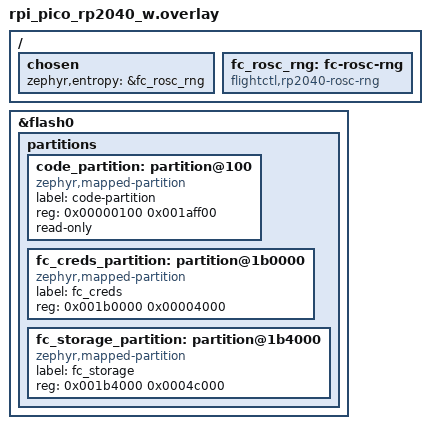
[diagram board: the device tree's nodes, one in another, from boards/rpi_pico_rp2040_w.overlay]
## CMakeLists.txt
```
# flightctl-mcu on Zephyr: the agent core, the Zephyr port and a small
# application. Built with port/zephyr/build.sh.
cmake_minimum_required(VERSION 3.20)
find_package(Zephyr REQUIRED HINTS $ENV{ZEPHYR_BASE})
project(flightctl_mcu)
# For mbedTLS too: it includes fc-mbedtls-user.h (prj.conf).
zephyr_include_directories(include)

set(ROOT ${CMAKE_CURRENT_LIST_DIR}/../..)

# WAMR (third_party/fetch-wamr.sh): fast interpreter only, as in the other
# builds.
enable_language(ASM)
set(WAMR_BUILD_PLATFORM "zephyr")
if(CONFIG_ARCH_POSIX)
    if(CMAKE_HOST_SYSTEM_PROCESSOR MATCHES "^(arm64|aarch64)")
        set(WAMR_BUILD_TARGET "AARCH64")
    else()
        set(WAMR_BUILD_TARGET "X86_64")
    endif()
elseif(CONFIG_CPU_CORTEX_M0PLUS OR CONFIG_CPU_CORTEX_M0)
    set(WAMR_BUILD_TARGET "THUMBV6M")
elseif(CONFIG_CPU_CORTEX_M)
    set(WAMR_BUILD_TARGET "THUMBV7EM")
elseif(CONFIG_XTENSA)
    set(WAMR_BUILD_TARGET "XTENSA")
else()
    message(FATAL_ERROR "flightctl-mcu: no WAMR target for this board yet")
endif()
set(WAMR_BUILD_INTERP 1)
set(WAMR_BUILD_FAST_INTERP 1)
set(WAMR_BUILD_AOT 0)
set(WAMR_BUILD_JIT 0)
set(WAMR_BUILD_LIBC_BUILTIN 0)
set(WAMR_BUILD_LIBC_WASI 0)
set(WAMR_BUILD_SIMD 0)
set(WAMR_BUILD_REF_TYPES 0)
# Instruction metering: an app call that runs past its budget traps, so an
# app in an endless loop can always be stopped (core/src/fc_apps.c).
set(WAMR_BUILD_INSTRUCTION_METERING 1)
set(WAMR_ROOT_DIR ${ROOT}/third_party/wamr)
include(${WAMR_ROOT_DIR}/build-scripts/runtime_lib.cmake)

# detools (third_party/fetch-detools.sh): firmware deltas, as in the other
# builds (CMakeLists.txt at the root).
set(DETOOLS ${ROOT}/third_party/detools/c)
set(DETOOLS_SRCS ${DETOOLS}/detools.c ${DETOOLS}/heatshrink/heatshrink_decoder.c)

target_sources(app PRIVATE
    src/main.c
    ${ROOT}/port/zephyr/fc_port_zephyr.c
    ${ROOT}/port/zephyr/fc_net_zephyr.c
    ${ROOT}/core/src/fc_agent.c
    ${ROOT}/core/src/fc_http.c
    ${ROOT}/core/src/fc_identity.c
    ${ROOT}/core/src/fc_oci.c
    ${ROOT}/core/src/fc_apps.c
    ${ROOT}/core/src/fc_appapi.c
    ${ROOT}/core/src/fc_board.c
    ${ROOT}/core/src/fc_resources.c
    ${ROOT}/core/src/fc_delta.c
    ${ROOT}/third_party/cjson/cJSON.c
    ${DETOOLS_SRCS}
    ${WAMR_RUNTIME_LIB_SOURCE})
# Boards with WiFi: the network, given at the factory, or in the field where
# the board can open an access point (with a DHCP server for installers).
if(CONFIG_WIFI)
    target_sources(app PRIVATE src/wifi.c)
endif()
if(CONFIG_WIFI AND CONFIG_NET_DHCPV4_SERVER)
    target_sources(app PRIVATE ${ROOT}/core/src/fc_prov.c)
endif()
if(CONFIG_FC_ENTROPY_RP2_ROSC)
    target_sources(app PRIVATE ${ROOT}/port/zephyr/fc_entropy_rp2.c)
endif()
# Infineon's WiFi driver (the Pico W's) keeps 20 packet buffers. Zephyr 4.5
# made them 2400 bytes each, 16 KB more than a board with 264 KB of RAM can
# give: 1600, what they were up to Zephyr 4.3 and what the board ran with, is
# an Ethernet frame and the chip's header.
if(CONFIG_WIFI_AIROC)
    zephyr_compile_definitions(AIROC_WIFI_PACKET_POOL_SIZE=1600)
endif()
# Raspberry Pi Pico boards: the USB console's conveniences.
if(CONFIG_SOC_FAMILY_RPI_PICO)
    target_sources(app PRIVATE src/board_rp2.c)
endif()
# The C heap is the port's unless the build keeps Zephyr's.
if(NOT CONFIG_COMMON_LIBC_MALLOC)
    target_sources(app PRIVATE ${ROOT}/port/zephyr/fc_heap_zephyr.c)
endif()
target_include_directories(app PRIVATE
    ${ROOT}/core/include ${ROOT}/core/src ${ROOT}/third_party/cjson ${ROOT}/port/zephyr
    ${DETOOLS} ${DETOOLS}/heatshrink)
# WAMR 2.4.5's Zephyr port includes <autoconf.h> and <version.h>, which Zephyr
# generates under zephyr/ and no longer puts on the include path as they are.
target_include_directories(app PRIVATE ${ZEPHYR_BINARY_DIR}/include/generated/zephyr)
target_compile_definitions(app PRIVATE
    CJSON_NESTING_LIMIT=32
    DETOOLS_CONFIG_FILE_IO=0 DETOOLS_CONFIG_COMPRESSION_NONE=0 DETOOLS_CONFIG_COMPRESSION_LZMA=0
    DETOOLS_CONFIG_COMPRESSION_CRLE=0 HEATSHRINK_DYNAMIC_ALLOC=1)
if(CONFIG_FC_AGENT_STACK_SIZE)
    target_compile_definitions(app PRIVATE FC_AGENT_STACK_SIZE=${CONFIG_FC_AGENT_STACK_SIZE})
endif()
set_source_files_properties(${DETOOLS_SRCS} PROPERTIES
    COMPILE_DEFINITIONS "malloc=fc_delta_alloc;free=fc_delta_free"
    COMPILE_OPTIONS "-w;-fwrapv")
```

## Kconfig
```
# flightctl-mcu application options.

config FC_SNTP_SERVER
	string "SNTP server the device takes the time from"
	default "pool.ntp.org"

config FC_HEAP_SIZE
	int "Size of the C heap (malloc), in bytes"
	default 163840
	help
	  Everything the agent allocates: TLS sessions, JSON documents, WASM
	  modules and their memory. The device reports how much of it is free.

config FC_AGENT_STACK_SIZE
	int "Stack of each of the agent's two threads, in bytes (0: the core's default)"
	default 0
	help
	  The core asks for 24 KB on a microcontroller. A board short of RAM can
	  give less once it has measured what the threads use (CONFIG_INIT_STACKS
	  and, on the Pico, the console's stack report).

config FC_ENTROPY_RP2_ROSC
	bool "Entropy from the RP2040's ring oscillator"
	depends on SOC_SERIES_RP2040
	depends on DT_HAS_FLIGHTCTL_RP2040_ROSC_RNG_ENABLED
	default y
	select ENTROPY_HAS_DRIVER
	select ENTROPY_NEEDS_PRNG
	help
	  The RP2040 has no random generator and Zephyr no entropy driver for
	  it. This is one (port/zephyr/fc_entropy_rp2.c), for the node the
	  board overlay adds and chooses as zephyr,entropy: the chip's ring
	  oscillator, from which Zephyr and PSA seed their generators.

config FC_FW_VERSION
	string "Firmware version, logged at boot"
	default "dev"

config FC_METRICS_INTERVAL
	int "Counters in customInfo read every (s)"
	default 3600
	help
	  The heap's low-water mark, traffic. The statuses in between repeat
	  the last values: Flight Control 1.4 logs an event for every change
	  in the status.

config FC_OTA_VERIFY_TIMEOUT
	int "Seconds a new firmware has to reach Flight Control before it is given up"
	default 150
	help
	  Counted from the boot into the new image. After it the device
	  restarts and MCUboot puts the previous image back.

config FC_TEST_SERVER_PORT
	int "Test only: force this agent endpoint port (0: off)"
	default 0
	help
	  For the test of the way back: a firmware that cannot reach Flight
	  Control whatever the device was provisioned with.

config FC_FW_PLATFORM
	string "The name of this board's firmware in a release"
	default BOARD
	help
	  A firmware release is an OCI index with an image per platform; the
	  device takes the one whose platform.architecture is this.

config FC_LOG_DEBUG
	bool "Log the agent's debug messages"
	default n

source "Kconfig.zephyr"
```

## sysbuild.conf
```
# Used only by builds with a bootloader (port/zephyr/build.sh on a board named
# .../mcuboot): MCUboot, two slots swapped with a way back, images signed
# with ECDSA P-256. The key is given by build.sh (.secrets/mcuboot-signing.pem).
SB_CONFIG_BOOTLOADER_MCUBOOT=y
SB_CONFIG_MCUBOOT_MODE_SWAP_USING_MOVE=y
SB_CONFIG_BOOT_SIGNATURE_TYPE_ECDSA_P256=y
```

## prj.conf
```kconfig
# flightctl-mcu on Zephyr: what the agent core needs from the system.
# Board-specific settings are in boards/.

# The core is POSIX: threads with the stack size they ask for, clocks, sleep.
CONFIG_POSIX_API=y
CONFIG_THREAD_STACK_INFO=y
CONFIG_DYNAMIC_THREAD=y
CONFIG_DYNAMIC_THREAD_ALLOC=y
CONFIG_DYNAMIC_THREAD_PREFER_ALLOC=y
CONFIG_MAIN_STACK_SIZE=16384
# POSIX mutexes come from a fixed pool (5 by default): the core takes 7, and
# mbedTLS's threading layer (include/fc-tf-psa-user.h) 7.
CONFIG_MAX_PTHREAD_MUTEX_COUNT=16
CONFIG_MAX_PTHREAD_COND_COUNT=8
CONFIG_REBOOT=y
CONFIG_HWINFO=y
# The C heap is the port's (port/zephyr/fc_heap_zephyr.c), which reports how
# much of it is free; its size is CONFIG_FC_HEAP_SIZE.
CONFIG_COMMON_LIBC_MALLOC=n
CONFIG_SYS_HEAP_RUNTIME_STATS=y
# CPU use for status.resources: cycles outside the idle threads.
CONFIG_THREAD_RUNTIME_STATS=y

# Storage: LittleFS on the fc_storage partition (port/zephyr).
CONFIG_FLASH=y
CONFIG_FLASH_MAP=y
CONFIG_FILE_SYSTEM=y
CONFIG_FILE_SYSTEM_LITTLEFS=y

# Network: TCP sockets, DNS, and SNTP for the time certificates are checked
# against.
CONFIG_NETWORKING=y
CONFIG_NET_IPV4=y
CONFIG_NET_IPV6=n
# One interface and the router DHCP gives: no table of static routes (new in
# Zephyr 4.5, and on by default).
CONFIG_NET_IPV4_ROUTE=n
CONFIG_NET_TCP=y
CONFIG_NET_UDP=y
CONFIG_NET_SOCKETS=y
# The agent keeps two connections to Flight Control and opens a third to the
# registry for an app or a firmware; DHCP and DNS have theirs. Zephyr's
# default of four in all refuses the third.
CONFIG_NET_MAX_CONN=10
CONFIG_NET_MAX_CONTEXTS=10
CONFIG_DNS_RESOLVER=y
# The agent's two threads may both look the server up at the same time.
CONFIG_DNS_NUM_CONCUR_QUERIES=3
CONFIG_SNTP=y

# mbedTLS 4.1, as in the other builds: TLS 1.3 with ECDSA P-256 keys, X.509
# and PKCS#10 requests. Its cryptography is PSA's (TF-PSA-Crypto), chosen
# below by what TLS 1.3 and the agent take from it. RSA only for a device key
# in hardware, which the core can make.
CONFIG_PSA_CRYPTO=y
CONFIG_MBEDTLS=y
CONFIG_MBEDTLS_BUILTIN=y
CONFIG_MBEDTLS_SSL_PROTO_TLS1_2=y
CONFIG_MBEDTLS_SSL_PROTO_TLS1_3=y
CONFIG_MBEDTLS_SSL_TLS1_3_KEY_EXCHANGE_MODE_EPHEMERAL_ENABLED=y
CONFIG_MBEDTLS_KEY_EXCHANGE_ECDHE_ECDSA_ENABLED=y
CONFIG_MBEDTLS_KEY_EXCHANGE_ECDHE_RSA_ENABLED=y
CONFIG_MBEDTLS_PSA_CRYPTO_C=y
# The key exchange, the signatures, HKDF, the two AEAD ciphers, the hashes.
CONFIG_PSA_WANT_ALG_ECDH=y
CONFIG_PSA_WANT_ALG_ECDSA=y
CONFIG_PSA_WANT_ALG_DETERMINISTIC_ECDSA=y
CONFIG_PSA_WANT_ALG_HKDF=y
CONFIG_PSA_WANT_ALG_HKDF_EXTRACT=y
CONFIG_PSA_WANT_ALG_HKDF_EXPAND=y
CONFIG_PSA_WANT_ALG_HMAC=y
CONFIG_PSA_WANT_ALG_SHA_256=y
CONFIG_PSA_WANT_ALG_SHA_384=y
CONFIG_PSA_WANT_ALG_GCM=y
# Field provisioning's session (core/src/fc_prov.c): X25519, then AES-CTR.
CONFIG_PSA_WANT_ALG_CTR=y
CONFIG_PSA_WANT_ALG_CHACHA20_POLY1305=y
CONFIG_PSA_WANT_ALG_TLS12_PRF=y
CONFIG_PSA_WANT_ECC_SECP_R1_256=y
CONFIG_PSA_WANT_ECC_SECP_R1_384=y
CONFIG_PSA_WANT_ECC_MONTGOMERY_255=y
CONFIG_PSA_WANT_KEY_TYPE_AES=y
CONFIG_PSA_WANT_KEY_TYPE_CHACHA20=y
CONFIG_PSA_WANT_KEY_TYPE_HMAC=y
CONFIG_PSA_WANT_KEY_TYPE_ECC_PUBLIC_KEY=y
CONFIG_PSA_WANT_KEY_TYPE_ECC_KEY_PAIR_IMPORT=y
CONFIG_PSA_WANT_KEY_TYPE_ECC_KEY_PAIR_EXPORT=y
CONFIG_PSA_WANT_KEY_TYPE_ECC_KEY_PAIR_GENERATE=y
CONFIG_PSA_WANT_KEY_TYPE_ECC_KEY_PAIR_DERIVE=y
CONFIG_PSA_WANT_ALG_RSA_PKCS1V15_SIGN=y
CONFIG_PSA_WANT_ALG_RSA_PSS=y
CONFIG_PSA_WANT_KEY_TYPE_RSA_PUBLIC_KEY=y
CONFIG_PSA_WANT_KEY_TYPE_RSA_KEY_PAIR_IMPORT=y
CONFIG_PSA_WANT_KEY_TYPE_RSA_KEY_PAIR_EXPORT=y
CONFIG_PSA_WANT_KEY_TYPE_RSA_KEY_PAIR_GENERATE=y
# PSA's random generator: mbedTLS's own (entropy gathered, then a DRBG), fed
# by Zephyr's entropy driver.
CONFIG_MBEDTLS_PSA_CRYPTO_LEGACY_RNG=y
CONFIG_MBEDTLS_CTR_DRBG_C=y
CONFIG_MBEDTLS_HMAC_DRBG_C=y
CONFIG_MBEDTLS_PEM_PARSE_C=y
CONFIG_MBEDTLS_PEM_WRITE_C=y
CONFIG_MBEDTLS_PK_PARSE_C=y
CONFIG_MBEDTLS_PK_WRITE_C=y
CONFIG_MBEDTLS_X509_CRT_PARSE_C=y
CONFIG_MBEDTLS_X509_CSR_WRITE_C=y
CONFIG_MBEDTLS_X509_CSR_PARSE_C=y
CONFIG_MBEDTLS_SSL_SERVER_NAME_INDICATION=y
CONFIG_MBEDTLS_HAVE_TIME_DATE=y
# A TLS connection keeps a buffer for each direction. Records from the server
# can be 16 KB; what the agent sends goes out in records of 4 KB, as in the
# ESP-IDF build: 12 KB less per connection.
CONFIG_MBEDTLS_SSL_IN_CONTENT_LEN=16384
CONFIG_MBEDTLS_SSL_OUT_CONTENT_LEN=4096
# mbedTLS allocates from the C heap, like everything else here: its PSA key
# slots too (static ones cost 38 KB of RAM, sized for the largest RSA key).
CONFIG_MBEDTLS_ENABLE_HEAP=n
CONFIG_MBEDTLS_PSA_STATIC_KEY_SLOTS=n
# The AES tables in flash, not RAM (9 KB).
CONFIG_MBEDTLS_AES_ROM_TABLES=y
CONFIG_MBEDTLS_USER_CONFIG_FILE="fc-mbedtls-user.h"
CONFIG_TF_PSA_CRYPTO_USER_CONFIG_FILE="fc-tf-psa-user.h"
CONFIG_ENTROPY_GENERATOR=y
```

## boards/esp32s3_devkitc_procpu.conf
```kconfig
# ESP32-S3-DevKitC (board esp32s3_devkitc/esp32s3/procpu): Xtensa LX7, 512 KB
# of RAM, 8 MB of flash, WiFi in the chip. Built with sysbuild
# (port/zephyr/build.sh does it), which is how Zephyr starts this board: MCUboot,
# then the application, signed, in the first slot.

CONFIG_WIFI=y
CONFIG_NET_MGMT=y
CONFIG_NET_MGMT_EVENT=y
CONFIG_NET_DHCPV4=y
# Where several access points carry the network: the strongest, not the
# first one heard. And back by itself after a drop.
CONFIG_ESP32_WIFI_STA_SCAN_ALL=y
CONFIG_ESP32_WIFI_STA_RECONNECT=y
# Field provisioning (src/wifi.c): an access point and a station at once, so
# that the network an installer gives is tried with the access point still up;
# the access point gives installers an address.
# WIFI_USAGE_MODE_STA_AP, not ESP32_WIFI_AP_STA_MODE alone: it also lets the
# WiFi network manager keep both interfaces, without which the access point's
# is taken for the station's and installers get no address.
CONFIG_WIFI_NM=y
CONFIG_WIFI_USAGE_MODE_STA_AP=y
CONFIG_NET_IF_MAX_IPV4_COUNT=2
CONFIG_NET_DHCPV4_SERVER=y
# The thread that serves it: Zephyr's 2.4 KB is too little on Xtensa, and its
# AP+STA sample gives it 4 KB.
CONFIG_NET_SOCKETS_SERVICE_STACK_SIZE=4096
# No ICMP probe of an address before it is offered (1 s per lease): the
# access point's network has only installers on it.
CONFIG_NET_DHCPV4_SERVER_ICMP_PROBE_TIMEOUT=0

# Firmware updates into the second slot.
CONFIG_STREAM_FLASH=y
CONFIG_IMG_MANAGER=y
CONFIG_MCUBOOT_IMG_MANAGER=y
CONFIG_IMG_ERASE_PROGRESSIVELY=y

# Zephyr says what a fatal error was before the port restarts the board
# (fc_port_zephyr.c); the minimal log only costs its messages.
CONFIG_LOG=y
CONFIG_LOG_MODE_MINIMAL=y
CONFIG_LOG_DEFAULT_LEVEL=1
CONFIG_THREAD_NAME=y

# Memory. Zephyr gives this chip's first core 372 KB of its RAM for data. The
# agent's threads get 16 KB of stack each instead of the core's 24 KB (they
# use 4.2 KB on the Pico W; Xtensa's register windows take more). The kernel
# heap is 96 KB: the WiFi driver takes 37 KB of it, and thread stacks come
# from the rest (the two agent threads, an app thread of 8 KB). The C heap,
# 123 KB instead of the default 160 KB, makes room for it and for the app
# interface's board map, handles and event queues (5 KB).
CONFIG_FC_AGENT_STACK_SIZE=16384
CONFIG_HEAP_MEM_POOL_SIZE=98304
CONFIG_FC_HEAP_SIZE=125952
```

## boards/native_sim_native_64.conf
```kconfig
# native_sim: the agent as a Linux process. Zephyr's kernel, POSIX layer, file
# system and mbedTLS are real; the network is the host's, through its sockets.
CONFIG_NET_DRIVERS=y
CONFIG_NET_SOCKETS_OFFLOAD=y
CONFIG_NET_NATIVE_OFFLOADED_SOCKETS=y
CONFIG_ETH_NATIVE_TAP=n
CONFIG_NET_L2_ETHERNET=n
# Seeded from the host's /dev/urandom at each start.
CONFIG_FAKE_ENTROPY_NATIVE_SIM=y
CONFIG_FAKE_ENTROPY_NATIVE_SIM_SEED_BY_DEFAULT=y
# A reboot starts the process again, as a board would start again.
CONFIG_NATIVE_SIM_REBOOT=y
# The flash is a file (--flash=PATH): the storage and credentials survive a
# restart.
CONFIG_FLASH_SIMULATOR=y
# A 64-bit host's frames: thread stacks (from the kernel heap) and the C
# heap are sized for that, not for a microcontroller.
CONFIG_HEAP_MEM_POOL_SIZE=2097152
CONFIG_FC_HEAP_SIZE=4194304
```

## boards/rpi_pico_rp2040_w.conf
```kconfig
# Raspberry Pi Pico W: RP2040 (Cortex-M0+, 264 KB of RAM, 2 MB of flash) and
# a CYW43439 for WiFi. Also read for the board started by MCUboot
# (rpi_pico/rp2040/w/mcuboot, which adds rpi_pico_rp2040_w_mcuboot.conf).
CONFIG_WIFI=y
CONFIG_NET_MGMT=y
CONFIG_NET_MGMT_EVENT=y
CONFIG_NET_DHCPV4=y
# No field provisioning (src/wifi.c) on this board: Infineon's driver in
# Zephyr 4.5 cannot open an access point on the CYW43439 (docs/ZEPHYR.md).

# Randomness. The RP2040 has no random generator and Zephyr no entropy driver
# for it: the port has one, on the chip's ring oscillator
# (CONFIG_FC_ENTROPY_RP2_ROSC, on by default with the overlay's node). PSA
# (TLS, the device key) and the rest of Zephyr (TCP sequence numbers, DNS
# query ids) seed their generators from it.

# Zephyr says what a fatal error was before the port restarts the board
# (fc_port_zephyr.c); the minimal log only costs its messages.
CONFIG_LOG=y
CONFIG_LOG_MODE_MINIMAL=y
CONFIG_LOG_DEFAULT_LEVEL=1
# The Cortex-M0+ has no memory protection: a marker at the end of each stack
# is checked instead, so that an overflow is reported, not suffered.
CONFIG_STACK_SENTINEL=y
CONFIG_THREAD_NAME=y

# LittleFS writes whole flash pages (256 bytes). Zephyr 4.3 dropped writes
# of less than a page on this chip (docs/ZEPHYR.md); 4.5 does them, and this
# stays as it was tried.
CONFIG_FS_LITTLEFS_PROG_SIZE=256
CONFIG_FS_LITTLEFS_CACHE_SIZE=256

# Memory. Measured on the board (CONFIG_INIT_STACKS): the agent's threads
# use 4.2 KB of stack with their TLS connections up, the main thread 3 KB;
# they get 10 KB and 8 KB instead of the 24 KB and 16 KB of roomier boards.
CONFIG_FC_AGENT_STACK_SIZE=10240
CONFIG_MAIN_STACK_SIZE=8192
# What is left of the 264 KB after 108 KB of static data (with the console
# on USB and the log; mbedTLS's threading layer and its POSIX mutexes took the
# last 2 KB from the C heap, the app interface's board map, handles and event
# queues 5 KB more): the kernel heap, which thread stacks come from (the two
# agent threads, an app thread of 8 KB) after the WiFi driver and USB have
# taken 14 KB of it; and the C heap.
CONFIG_HEAP_MEM_POOL_SIZE=46080
CONFIG_FC_HEAP_SIZE=105472
```

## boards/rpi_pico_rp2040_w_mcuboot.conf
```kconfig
# Raspberry Pi Pico W started by MCUboot (board rpi_pico/rp2040/w/mcuboot,
# built with sysbuild: port/zephyr/build.sh does it): firmware updates into the
# second slot. The rest of the board's configuration is
# rpi_pico_rp2040_w.conf, which sysbuild.cmake adds.
CONFIG_STREAM_FLASH=y
CONFIG_IMG_MANAGER=y
CONFIG_MCUBOOT_IMG_MANAGER=y
# The slot is erased sector by sector as the image arrives: erasing 832 KB at
# once keeps interrupts off for seconds.
CONFIG_IMG_ERASE_PROGRESSIVELY=y
# What a release's index calls this board (platform.architecture).
CONFIG_FC_FW_PLATFORM="rpi_pico_w"
# What Zephyr gives the Pico W and forgets for this variant of it: the
# WiFi chip (the default is another one, with other firmware).
CONFIG_CYW43439=y
```

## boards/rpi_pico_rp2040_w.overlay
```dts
/*
 * The Pico's 2 MB of flash: the application, then the credentials and the
 * storage in the last 320 KB (where Zephyr's layout for MCUboot on this board
 * puts its storage partition).
 */
/delete-node/ &code_partition;

&flash0 {
	partitions {
		code_partition: partition@100 {
			compatible = "zephyr,mapped-partition";
			label = "code-partition";
			reg = <0x00000100 0x001aff00>;
			read-only;
		};
		fc_creds_partition: partition@1b0000 {
			compatible = "zephyr,mapped-partition";
			label = "fc_creds";
			reg = <0x001b0000 0x00004000>;
		};
		fc_storage_partition: partition@1b4000 {
			compatible = "zephyr,mapped-partition";
			label = "fc_storage";
			reg = <0x001b4000 0x0004c000>;
		};
	};
};

/ {
	chosen {
		zephyr,entropy = &fc_rosc_rng;
	};

	/* The ring oscillator as the entropy device (port/zephyr/fc_entropy_rp2.c). */
	fc_rosc_rng: fc-rosc-rng {
		compatible = "flightctl,rp2040-rosc-rng";
		status = "okay";
	};
};
```

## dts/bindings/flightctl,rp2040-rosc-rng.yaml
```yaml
# The RP2040's ring oscillator as Zephyr's entropy device
# (port/zephyr/fc_entropy_rp2.c). The board overlay has the node and makes it
# the chosen zephyr,entropy.
description: Random bits from the RP2040's ring oscillator

compatible: "flightctl,rp2040-rosc-rng"

include: base.yaml
```

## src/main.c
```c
/*
 * flightctl-mcu on Zephyr: credentials from the fc_creds partition, the
 * time from SNTP, then the Flight Control agent.
 */
#include <stdio.h>
#include <stdlib.h>
#include <string.h>
#include <time.h>

#include <zephyr/kernel.h>
#include <zephyr/net/sntp.h>
#include <zephyr/storage/flash_map.h>
#include <zephyr/sys/byteorder.h>

#include "cJSON.h"
#include "fc_agent.h"
#include "fc_port.h"
#include "fc_port_zephyr.h"
#include "fc_wifi_zephyr.h"

/* The fc_creds partition, written by tools/provision.py --format zephyr:
 * "FCC1", the length of what follows (32 bits, little-endian), then a JSON
 * object with the fields of the ESP-IDF firmware's fc_creds: server_host,
 * server_port, ca, enroll_crt, enroll_key, signing_pub, labels. */
#define CREDS_MAGIC "FCC1"
#define CREDS_MAX   (12 * 1024)

static cJSON *load_creds(void)
{
    const struct flash_area *fa;
    if (flash_area_open(PARTITION_ID(fc_creds_partition), &fa) != 0) {
        return NULL;
    }
    uint8_t hdr[8];
    cJSON *creds = NULL;
    if (flash_area_read(fa, 0, hdr, sizeof(hdr)) == 0 && memcmp(hdr, CREDS_MAGIC, 4) == 0) {
        uint32_t len = sys_get_le32(hdr + 4);
        char *json = len <= CREDS_MAX && len + sizeof(hdr) <= fa->fa_size ? malloc(len + 1) : NULL;
        if (json != NULL && flash_area_read(fa, sizeof(hdr), json, len) == 0) {
            json[len] = '\0';
            creds = cJSON_Parse(json);
        }
        free(json);
    }
    flash_area_close(fa);
    return creds;
}

static const char *str(const cJSON *creds, const char *name)
{
    const char *v = cJSON_GetStringValue(cJSON_GetObjectItem(creds, name));
    return v != NULL && v[0] != '\0' ? v : NULL;
}

/* Certificates are checked against the clock, and a device knows no time. */
#ifdef CONFIG_ARCH_POSIX
#include "native_rtc.h"

/* native_sim: the simulated real-time clock starts at the host's time. */
static void wait_for_time(void)
{
    uint64_t us = native_rtc_gettime_us(RTC_CLOCK_REALTIME);
    struct timespec ts = {.tv_sec = (time_t)(us / 1000000), .tv_nsec = (long)(us % 1000000) * 1000};
    clock_settime(CLOCK_REALTIME, &ts);
}
#else
static void wait_for_time(void)
{
    for (;;) {
        struct sntp_time t;
        if (sntp_simple(CONFIG_FC_SNTP_SERVER, 5000, &t) == 0) {
            struct timespec ts = {.tv_sec = (time_t)t.seconds};
            clock_settime(CLOCK_REALTIME, &ts);
            return;
        }
        fc_port_log(FC_LOG_WARN, "waiting for the time from %s...", CONFIG_FC_SNTP_SERVER);
        k_sleep(K_SECONDS(5));
    }
}
#endif


/* Simulated hardware for WASM apps, as on the host: a chip temperature that
 * swings 30..46 C over two minutes, and an LED (led0) printed when it
 * changes. No GPIO yet. */
static int sim_sensor(const char *name, int32_t *value)
{
    if (strcmp(name, "die_temp") != 0) {
        return FC_HW_ENOENT;
    }
    long t = (long)(k_uptime_get() / 1000) % 120;
    *value = 30000 + (int32_t)(t < 60 ? t : 120 - t) * 266;
    return 0;
}

static int sim_led_rgb(const fc_hw_led_t *led, uint8_t r, uint8_t g, uint8_t b)
{
    static int32_t last = -1;
    int32_t v = (r << 16) | (g << 8) | b;
    if (v != last) {
        printk("LED r=%d g=%d b=%d\n", (int)r, (int)g, (int)b);
        last = v;
    }
    return 0;
}

static int sim_led_open(const fc_hw_led_t *led)
{
    return 0;
}

static void sim_led_close(const fc_hw_led_t *led)
{
    sim_led_rgb(led, 0, 0, 0);
}

static char *sim_board(void)
{
    return strdup("{\"led\": {\"led0\": {\"dt\": \"simulated\"}}}");
}

static const fc_hw_t s_hw = {
    .board = CONFIG_BOARD_TARGET,
    .firmware = CONFIG_FC_FW_VERSION,
    .board_defaults = sim_board,
    .led_open = sim_led_open,
    .led_rgb = sim_led_rgb,
    .led_close = sim_led_close,
    .sensor_read = sim_sensor,
};

/* Nothing can be done, and maybe no one was watching when it was first
 * said: say it again every few seconds. */
static void stop(const char *why)
{
    for (;;) {
        fc_port_log(FC_LOG_ERROR, "%s", why);
        k_sleep(K_SECONDS(10));
    }
}

int main(void)
{
    fc_port_log(FC_LOG_INFO, "flightctl-mcu %s on Zephyr, board %s", CONFIG_FC_FW_VERSION, CONFIG_BOARD_TARGET);
    if (fc_port_zephyr_init() != 0) {
        stop("cannot mount the storage (the fc_storage partition)");
    }
    cJSON *creds = load_creds();
    const char *host = str(creds, "server_host");
    const cJSON *port = cJSON_GetObjectItem(creds, "server_port");
    if (host == NULL || str(creds, "ca") == NULL || str(creds, "enroll_crt") == NULL ||
        str(creds, "enroll_key") == NULL) {
        stop("no credentials: write the fc_creds partition (tools/provision.py --format zephyr)");
    }
    /* {"k": "v", ...} to the {k, v, ..., NULL} the agent takes */
    static const char *labels[33];
    int n = 0;
    const cJSON *l;
    cJSON_ArrayForEach(l, cJSON_GetObjectItem(creds, "labels")) {
        if (n < 30 && cJSON_IsString(l)) {
            labels[n++] = l->string;
            labels[n++] = l->valuestring;
        }
    }

#ifdef CONFIG_WIFI
    fc_wifi_up(creds);
#endif
    wait_for_time();
    size_t heap, heap_free, heap_min, kheap, kheap_free;
    fc_heap_stats(&heap, &heap_free, &heap_min);
    fc_kernel_heap_stats(&kheap, &kheap_free);
    fc_port_log(FC_LOG_INFO, "memory: heap %u of %u bytes free, for thread stacks %u of %u", (unsigned)heap_free,
                (unsigned)heap, (unsigned)kheap_free, (unsigned)kheap);
    fc_agent_config_t cfg = {
        .server_host = host,
        .server_port = CONFIG_FC_TEST_SERVER_PORT != 0 ? CONFIG_FC_TEST_SERVER_PORT
                       : cJSON_IsNumber(port)           ? port->valueint
                                                        : 8443,
        .ca_pem = str(creds, "ca"),
        .enrollment_cert_pem = str(creds, "enroll_crt"),
        .enrollment_key_pem = str(creds, "enroll_key"),
        .signing_pub_pem = str(creds, "signing_pub"),
        .labels = labels,
        .agent_version = "flightctl-mcu/0.1.0",
        .status_interval_s = 60,
        .metrics_interval_s = CONFIG_FC_METRICS_INTERVAL,
        .ota_verify_timeout_s = CONFIG_FC_OTA_VERIFY_TIMEOUT,
        .hw = &s_hw,
    };
    fc_agent_run(&cfg);
    stop("the agent stopped");
    return 1;
}
```

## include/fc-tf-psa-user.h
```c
/* Added to Zephyr's TF-PSA-Crypto configuration (CONFIG_TF_PSA_CRYPTO_USER_CONFIG_FILE). */

/* The agent calls PSA from several threads at once (status, spec, app
 * downloads): PSA's key table needs the threading layer, on Zephyr's POSIX
 * mutexes (CONFIG_POSIX_API). Zephyr has no Kconfig option for it. */
#define MBEDTLS_THREADING_C
#define MBEDTLS_THREADING_PTHREAD
```

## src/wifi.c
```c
/*
 * The WiFi network, on boards that have one: given at the factory (fc_creds,
 * wifi_ssid), or by an installer in the field (core/src/fc_prov.c), as the
 * ESP-IDF firmware does it (docs/PROVISIONING.md).
 *
 * In the field: with no network at the factory and none kept from an earlier
 * provisioning, a device that has a proof of possession (prov_pop) scans for
 * networks, then opens an access point, FC-xxxxxx (the end of its MAC),
 * protected by that proof, and serves Espressif's provisioning protocol on
 * 192.168.4.1:80. Where the radio can be an access point and a station at
 * once (Espressif's, CONFIG_ESP32_WIFI_AP_STA_MODE), it tries the network
 * with the access point still up and tells the installer whether it joined;
 * one that cannot closes the access point to try it, and opens it again if it
 * fails. A network is kept (fc_port_kv "wifi") once the device has joined it,
 * for the credentials it was given with: writing fc_creds again forgets it.
 * Only on boards built with a DHCP server (CONFIG_NET_DHCPV4_SERVER): not on
 * the Pico W, whose driver cannot open an access point (docs/ZEPHYR.md).
 */
#include <stdio.h>
#include <stdlib.h>
#include <string.h>

#include <zephyr/kernel.h>
#include <zephyr/net/dhcpv4_server.h>
#include <zephyr/net/net_if.h>
#include <zephyr/net/net_mgmt.h>
#include <zephyr/net/wifi_mgmt.h>

#include "cJSON.h"
#include "fc_crypto.h"
#include "fc_port.h"
#include "fc_prov.h"
#include "fc_wifi_zephyr.h"

/* Where several access points carry the network, the Pico W's chip may join a
 * far one (Infineon's driver takes no access point's address, and telling the
 * chip to prefer the strongest changed nothing): there, name lookups and
 * handshakes time out. A weak join is given up for another one, a few times.
 * Espressif's driver scans every channel and joins the strongest
 * (CONFIG_ESP32_WIFI_STA_SCAN_ALL, in the board's file). */
#define WIFI_GOOD_DBM (-60)
#define WIFI_JOINS    5
/* A network from the field, tried with the access point closed: so many
 * times before the access point opens again. */
#define FIELD_TRIES 3
#define KV_WIFI     "wifi"

static K_SEM_DEFINE(s_ip_up, 0, 1);
static K_SEM_DEFINE(s_scan_done, 0, 1);
static struct net_mgmt_event_callback s_ip_cb, s_wifi_cb;
static struct net_if *s_sta, *s_ap;

/* The network being tried while the access point is up */
static volatile int s_connect_status = -1; /* -1: no result yet */
static volatile int s_sta_ip;

/* The networks seen, while provisioning only: on the heap, not in static RAM. */
static fc_prov_ap_t *s_aps;
static int s_ap_count;

static void on_ip(struct net_mgmt_event_callback *cb, uint64_t event, struct net_if *iface)
{
    if (event == NET_EVENT_IPV4_ADDR_ADD && iface == s_sta) {
        s_sta_ip = 1;
        k_sem_give(&s_ip_up);
    }
}

static uint8_t auth_of(enum wifi_security_type t)
{
    switch (t) {
    case WIFI_SECURITY_TYPE_NONE:
        return FC_PROV_AUTH_OPEN;
    case WIFI_SECURITY_TYPE_WEP:
        return FC_PROV_AUTH_WEP;
    case WIFI_SECURITY_TYPE_WPA_PSK:
        return FC_PROV_AUTH_WPA_PSK;
    case WIFI_SECURITY_TYPE_SAE:
        return FC_PROV_AUTH_WPA3_PSK;
    case WIFI_SECURITY_TYPE_WPA_AUTO_PERSONAL:
        return FC_PROV_AUTH_WPA2_WPA3_PSK;
    case WIFI_SECURITY_TYPE_EAP:
        return FC_PROV_AUTH_WPA2_ENTERPRISE;
    default:
        return FC_PROV_AUTH_WPA2_PSK;
    }
}

/* A scan result: kept if it is a network not seen yet (the strongest of its
 * access points), the strongest FC_PROV_SCAN_MAX of them. */
static void scan_result(const struct wifi_scan_result *r)
{
    if (s_aps == NULL || r->ssid_length == 0 || r->ssid_length > 32) {
        return; /* hidden */
    }
    int at = -1;
    for (int i = 0; i < s_ap_count; i++) {
        if (strlen(s_aps[i].ssid) == r->ssid_length && memcmp(s_aps[i].ssid, r->ssid, r->ssid_length) == 0) {
            if (r->rssi <= s_aps[i].rssi) {
                return;
            }
            at = i;
            break;
        }
    }
    if (at < 0) {
        if (s_ap_count < FC_PROV_SCAN_MAX) {
            at = s_ap_count++;
        } else {
            at = 0; /* the weakest, if this one is stronger */
            for (int i = 1; i < s_ap_count; i++) {
                if (s_aps[i].rssi < s_aps[at].rssi) {
                    at = i;
                }
            }
            if (r->rssi <= s_aps[at].rssi) {
                return;
            }
        }
    }
    fc_prov_ap_t *ap = &s_aps[at];
    memset(ap, 0, sizeof(*ap));
    memcpy(ap->ssid, r->ssid, r->ssid_length);
    memcpy(ap->bssid, r->mac, r->mac_length < 6 ? r->mac_length : 6);
    ap->rssi = r->rssi;
    ap->channel = r->channel;
    ap->auth = auth_of(r->security);
}

static void on_wifi(struct net_mgmt_event_callback *cb, uint64_t event, struct net_if *iface)
{
    if (event == NET_EVENT_WIFI_SCAN_RESULT) {
        scan_result(cb->info);
    } else if (event == NET_EVENT_WIFI_SCAN_DONE) {
        k_sem_give(&s_scan_done);
    } else if (event == NET_EVENT_WIFI_CONNECT_RESULT && iface == s_sta) {
        s_connect_status = ((const struct wifi_status *)cb->info)->status;
    } else if (event == NET_EVENT_WIFI_AP_STA_CONNECTED || event == NET_EVENT_WIFI_AP_STA_DISCONNECTED) {
        const struct wifi_ap_sta_info *sta = cb->info;
        fc_port_log(FC_LOG_INFO, "provisioning: a device %s the access point (..:%02x:%02x)",
                    event == NET_EVENT_WIFI_AP_STA_CONNECTED ? "joined" : "left", sta->mac[4], sta->mac[5]);
    }
}

static struct wifi_connect_req_params params(const char *ssid, const char *pass)
{
    return (struct wifi_connect_req_params){
        .ssid = (const uint8_t *)ssid,
        .ssid_length = (uint8_t)strlen(ssid),
        .psk = (const uint8_t *)pass,
        .psk_length = pass != NULL ? (uint8_t)strlen(pass) : 0,
        .security = pass != NULL && pass[0] != '\0' ? WIFI_SECURITY_TYPE_PSK : WIFI_SECURITY_TYPE_NONE,
        .channel = WIFI_CHANNEL_ANY,
        .band = WIFI_FREQ_BAND_2_4_GHZ,
        .mfp = WIFI_MFP_OPTIONAL,
    };
}

/* Joins a network and waits for an address: 0, or -1 after `tries` tries
 * (0: until it works). */
static int join(const char *ssid, const char *pass, int tries)
{
    struct wifi_connect_req_params p = params(ssid, pass);
    int joins = 0;
    for (int t = 1;; t++) {
        fc_port_log(FC_LOG_INFO, "WiFi: joining \"%s\"", ssid);
        k_sem_reset(&s_ip_up);
        if (net_mgmt(NET_REQUEST_WIFI_CONNECT, s_sta, &p, sizeof(p)) == 0) {
            struct wifi_iface_status st = {0};
            int known = net_mgmt(NET_REQUEST_WIFI_IFACE_STATUS, s_sta, &st, sizeof(st)) == 0;
            /* Infineon's driver has joined when the request returns; others
             * (Espressif's) join after it, and choose the access point
             * themselves. */
            if (IS_ENABLED(CONFIG_WIFI_AIROC) && known && st.rssi < WIFI_GOOD_DBM && ++joins < WIFI_JOINS) {
                fc_port_log(FC_LOG_INFO, "WiFi: access point ..:%02x:%02x is weak (%d dBm), looking for a nearer one",
                            st.bssid[4], st.bssid[5], st.rssi);
                net_mgmt(NET_REQUEST_WIFI_DISCONNECT, s_sta, NULL, 0);
                k_sleep(K_SECONDS(1));
                t--;
                continue;
            }
            if (k_sem_take(&s_ip_up, K_SECONDS(30)) == 0) {
                known = net_mgmt(NET_REQUEST_WIFI_IFACE_STATUS, s_sta, &st, sizeof(st)) == 0;
                if (known) {
                    fc_port_log(FC_LOG_INFO, "WiFi: connected (channel %d, %d dBm, access point ..:%02x:%02x)",
                                st.channel, st.rssi, st.bssid[4], st.bssid[5]);
                } else {
                    fc_port_log(FC_LOG_INFO, "WiFi: connected");
                }
                return 0;
            }
            net_mgmt(NET_REQUEST_WIFI_DISCONNECT, s_sta, NULL, 0);
        }
        if (tries > 0 && t >= tries) {
            return -1;
        }
        fc_port_log(FC_LOG_WARN, "WiFi: no connection yet, trying again");
        k_sleep(K_SECONDS(5));
    }
}

/* ---- in the field ---------------------------------------------------------- */

/* The credentials partition, by a hash of it: a network given in the field is
 * kept for these credentials only. Writing the partition again (a new proof of
 * possession, another installation) forgets it, and the device asks again. */
static char s_creds_id[17];

static void creds_id(const cJSON *creds)
{
    char *text = cJSON_PrintUnformatted(creds);
    unsigned char d[32];
    fc_sha256_t h;
    fc_sha256_start(&h);
    fc_sha256_update(&h, text, text != NULL ? strlen(text) : 0);
    fc_sha256_finish(&h, d);
    free(text);
    for (int i = 0; i < 8; i++) {
        snprintf(s_creds_id + 2 * i, 3, "%02x", d[i]);
    }
}

#ifdef CONFIG_NET_DHCPV4_SERVER

/* With the access point up (fc_prov_config_t.join): the station interface
 * joins on its own, and on_wifi / on_ip say how it went. */
static int field_join(void *ctx, const char *ssid, const char *pass)
{
    if (s_ap == s_sta) {
        return -1; /* one interface: the access point must close first */
    }
    static struct wifi_connect_req_params p;
    p = params(ssid, pass);
    s_connect_status = -1;
    s_sta_ip = 0;
    net_mgmt(NET_REQUEST_WIFI_DISCONNECT, s_sta, NULL, 0);
    return net_mgmt(NET_REQUEST_WIFI_CONNECT, s_sta, &p, sizeof(p)) == 0 ? 0 : -1;
}

static fc_prov_join_t field_join_state(void *ctx)
{
    int st = s_connect_status;
    if (s_sta_ip) {
        return FC_PROV_JOINED;
    }
    if (st < 0 || st == WIFI_STATUS_CONN_SUCCESS) {
        return FC_PROV_JOINING;
    }
    net_mgmt(NET_REQUEST_WIFI_DISCONNECT, s_sta, NULL, 0);
    return st == WIFI_STATUS_CONN_WRONG_PASSWORD ? FC_PROV_BAD_PASSWORD : FC_PROV_NOT_FOUND;
}

static void scan(void)
{
    s_ap_count = 0;
    k_sem_reset(&s_scan_done);
    if (net_mgmt(NET_REQUEST_WIFI_SCAN, s_sta, NULL, 0) != 0 || k_sem_take(&s_scan_done, K_SECONDS(15)) != 0) {
        fc_port_log(FC_LOG_WARN, "WiFi: the scan failed; the installer will have to type the network's name");
    }
}

/* The access point, its address and its DHCP server: 0, or -1. */
static int ap_open(const char *pop, char name[16])
{
    struct net_linkaddr *mac = net_if_get_link_addr(s_ap);
    snprintf(name, 16, "FC-%02X%02X%02X", mac->addr[3], mac->addr[4], mac->addr[5]);
    struct wifi_connect_req_params p = params(name, pop);
    p.channel = 6;
    p.bandwidth = WIFI_FREQ_BANDWIDTH_20MHZ;
    struct net_in_addr addr = {.s4_addr = {192, 168, 4, 1}}, mask = {.s4_addr = {255, 255, 255, 0}},
                       pool = {.s4_addr = {192, 168, 4, 2}};
    /* The address, the gateway installers are given, and the DHCP server
     * first, then the access point, as Zephyr's AP+STA sample does. */
    net_if_ipv4_addr_add(s_ap, &addr, NET_ADDR_MANUAL, 0);
    net_if_ipv4_set_netmask_by_addr(s_ap, &addr, &mask);
    net_if_ipv4_set_gw(s_ap, &addr);
    int rc = net_dhcpv4_server_start(s_ap, &pool);
    if (rc != 0) {
        fc_port_log(FC_LOG_ERROR, "WiFi: cannot start the DHCP server (%d)", rc);
    }
    if (net_mgmt(NET_REQUEST_WIFI_AP_ENABLE, s_ap, &p, sizeof(p)) != 0) {
        fc_port_log(FC_LOG_ERROR, "WiFi: cannot open the provisioning access point");
        net_dhcpv4_server_stop(s_ap);
        net_if_ipv4_addr_rm(s_ap, &addr);
        return -1;
    }
    return 0;
}

static void ap_close(void)
{
    struct net_in_addr addr = {.s4_addr = {192, 168, 4, 1}}, none = {0};
    net_dhcpv4_server_stop(s_ap);
    net_if_ipv4_set_gw(s_ap, &none);
    net_if_ipv4_addr_rm(s_ap, &addr);
    net_mgmt(NET_REQUEST_WIFI_AP_DISABLE, s_ap, NULL, 0);
}

static void keep(const char *ssid, const char *pass)
{
    cJSON *o = cJSON_CreateObject();
    cJSON_AddStringToObject(o, "ssid", ssid);
    cJSON_AddStringToObject(o, "pass", pass);
    cJSON_AddStringToObject(o, "creds", s_creds_id);
    char *text = cJSON_PrintUnformatted(o);
    cJSON_Delete(o);
    if (text == NULL || fc_port_kv_set(KV_WIFI, text, strlen(text)) != 0) {
        fc_port_log(FC_LOG_WARN, "WiFi: cannot keep the network: it will be asked for again after a restart");
    }
    free(text);
}

static void field_provisioning(const char *pop)
{
    char ssid[33], pass[65];
    for (;;) {
        s_aps = calloc(FC_PROV_SCAN_MAX, sizeof(*s_aps));
        scan();
        char name[16];
        while (ap_open(pop, name) != 0) {
            k_sleep(K_SECONDS(10));
        }
        fc_port_log(FC_LOG_WARN,
                    "no WiFi network: field provisioning on access point %s (password: the proof of possession)", name);
        fc_prov_config_t cfg = {
            .pop = pop,
            .port = 80,
            .aps = s_aps,
            .ap_count = s_ap_count,
            .join = field_join,
            .join_state = field_join_state,
        };
        int joined = 0;
        int rc = fc_prov_serve(&cfg, ssid, pass, &joined);
        ap_close();
        free(s_aps);
        s_aps = NULL;
        s_ap_count = 0;
        if (rc != 0) {
            k_sleep(K_SECONDS(10));
            continue;
        }
        if (joined || join(ssid, pass, FIELD_TRIES) == 0) {
            keep(ssid, pass);
            fc_port_log(FC_LOG_INFO, "field provisioning: done");
            memset(pass, 0, sizeof(pass));
            return;
        }
        fc_port_log(FC_LOG_WARN, "WiFi: cannot join \"%s\": opening the access point again", ssid);
    }
}
#endif /* CONFIG_NET_DHCPV4_SERVER */

void fc_wifi_up(const cJSON *creds)
{
    s_sta = net_if_get_wifi_sta();
    s_ap = IS_ENABLED(CONFIG_ESP32_WIFI_AP_STA_MODE) ? net_if_get_wifi_sap() : s_sta;
    if (s_ap == NULL) {
        s_ap = s_sta;
    }
    net_mgmt_init_event_callback(&s_ip_cb, on_ip, NET_EVENT_IPV4_ADDR_ADD);
    net_mgmt_add_event_callback(&s_ip_cb);
    net_mgmt_init_event_callback(&s_wifi_cb, on_wifi,
                                 NET_EVENT_WIFI_SCAN_RESULT | NET_EVENT_WIFI_SCAN_DONE | NET_EVENT_WIFI_CONNECT_RESULT |
                                     NET_EVENT_WIFI_AP_STA_CONNECTED | NET_EVENT_WIFI_AP_STA_DISCONNECTED);
    net_mgmt_add_event_callback(&s_wifi_cb);

    const char *ssid = cJSON_GetStringValue(cJSON_GetObjectItem(creds, "wifi_ssid"));
    const char *pop = cJSON_GetStringValue(cJSON_GetObjectItem(creds, "prov_pop"));
    (void)pop; /* without an access point (the Pico W) there is no provisioning in the field */
    if (ssid != NULL && ssid[0] != '\0') {
        join(ssid, cJSON_GetStringValue(cJSON_GetObjectItem(creds, "wifi_pass")), 0);
        return;
    }
    char *kept = NULL;
    size_t len = 0;
    creds_id(creds);
    if (fc_port_kv_get(KV_WIFI, &kept, &len) == 0) {
        cJSON *w = cJSON_Parse(kept);
        free(kept);
        const char *s = cJSON_GetStringValue(cJSON_GetObjectItem(w, "ssid"));
        const char *id = cJSON_GetStringValue(cJSON_GetObjectItem(w, "creds"));
        if (s != NULL && (id == NULL || strcmp(id, s_creds_id) != 0)) {
            fc_port_log(FC_LOG_INFO, "WiFi: the credentials were written again: the network \"%s\" is forgotten", s);
            fc_port_kv_del(KV_WIFI);
            s = NULL;
        }
        if (s != NULL) {
            join(s, cJSON_GetStringValue(cJSON_GetObjectItem(w, "pass")), 0);
            cJSON_Delete(w);
            return;
        }
        cJSON_Delete(w);
    }
#ifdef CONFIG_NET_DHCPV4_SERVER
    if (pop != NULL && pop[0] != '\0') {
        field_provisioning(pop);
        return;
    }
#endif
    for (;;) {
        fc_port_log(FC_LOG_ERROR, IS_ENABLED(CONFIG_NET_DHCPV4_SERVER)
                                      ? "no WiFi network: provision it (provision.py --wifi-ssid, or --pop to set "
                                        "it in the field)"
                                      : "no WiFi network: provision it (provision.py --wifi-ssid); this board has "
                                        "no provisioning in the field");
        k_sleep(K_SECONDS(10));
    }
}
```
